VERSION ""

NS_ :

BS_:

BU_: Accelero_Sensor

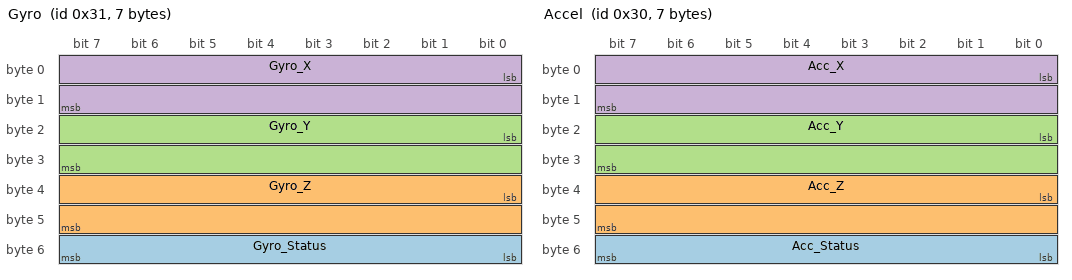
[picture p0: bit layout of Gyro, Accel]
BO_ 49 Gyro: 7 Accelero_Sensor
 SG_ Gyro_Status : 48|8@1+ (1,0) [0|255] "" Vector__XXX
 SG_ Gyro_Z : 32|16@1- (0.00763,0) [0|0] "deg/s" Vector__XXX
 SG_ Gyro_Y : 16|16@1- (0.00763,0) [0|0] "deg/s" Vector__XXX
 SG_ Gyro_X : 0|16@1- (0.00763,0) [0|0] "deg/s" Vector__XXX

BO_ 48 Accel: 7 Accelero_Sensor
 SG_ Acc_Status : 48|8@1+ (1,0) [0|0] "" Vector__XXX
 SG_ Acc_Z : 32|16@1- (6.1E-005,0) [-12|12] "g" Vector__XXX
 SG_ Acc_Y : 16|16@1- (6.1E-005,0) [-12|12] "g" Vector__XXX
 SG_ Acc_X : 0|16@1- (6.1E-005,0) [-12|12] "g" Vector__XXX

BA_DEF_  "BusType" STRING ;
BA_DEF_DEF_  "BusType" "CAN";
